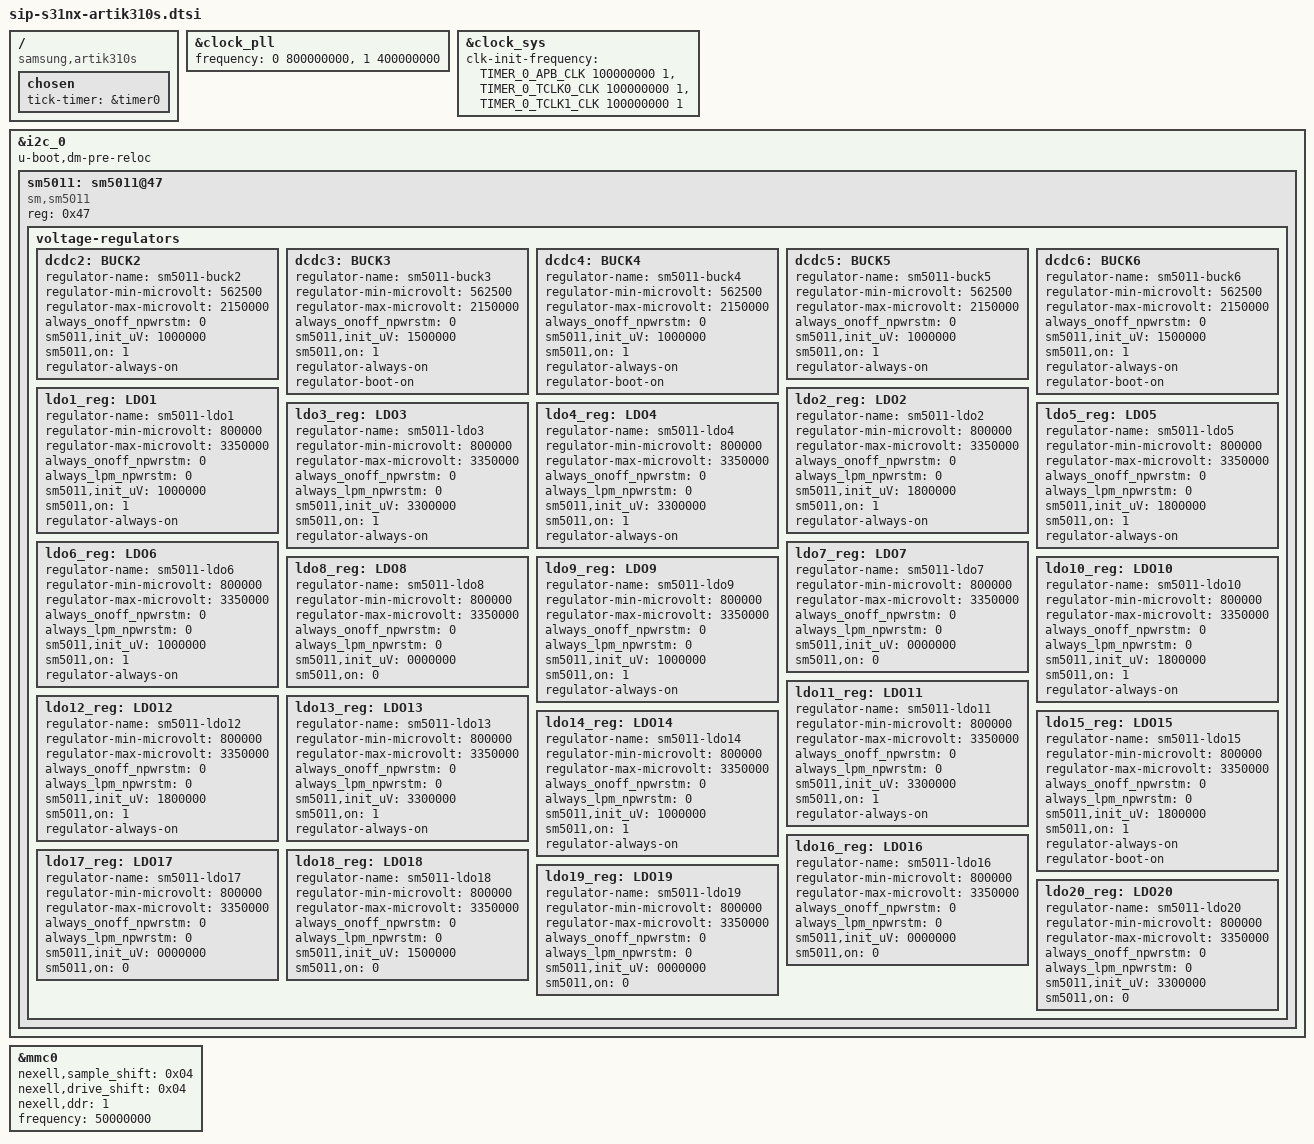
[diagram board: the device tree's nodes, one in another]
/*
 * (C) Copyright 2018 Nexell
 * JungHyun, Kim <jhkim@nexell.co.kr>
 *
 * SPDX-License-Identifier:      GPL-2.0+
 */

#include "sip-s31nx.dtsi"

/ {
	compatible = "samsung,artik310s", "nexell,nxp3220";

	chosen {
		tick-timer = &timer0;
	};
};

&clock_pll {
	frequency = <0 800000000>,
		    <1 400000000>;
};

&clock_sys {
	clk-init-frequency = <TIMER_0_APB_CLK 100000000 1>,
			     <TIMER_0_TCLK0_CLK 100000000 1>,
			     <TIMER_0_TCLK1_CLK 100000000 1>;
};

&i2c_0 {
	status = "okay";
	u-boot,dm-pre-reloc;
	#address-cells = <1>;
	#size-cells = <0>;

	sm5011: sm5011@47 {
		compatible = "sm,sm5011";
		reg = <0x47>;

		voltage-regulators {
			/* BUCK */
			dcdc2: BUCK2 {
				regulator-name = "sm5011-buck2";
				regulator-min-microvolt = <562500>;
				regulator-max-microvolt = <2150000>;
				always_onoff_npwrstm = <0>;
				sm5011,init_uV = <1000000>;
				sm5011,on = <1>;
				regulator-always-on;
			};

			dcdc3: BUCK3 {
				regulator-name = "sm5011-buck3";
				regulator-min-microvolt = <562500>;
				regulator-max-microvolt = <2150000>;
				always_onoff_npwrstm = <0>;
				sm5011,init_uV = <1500000>;
				sm5011,on = <1>;
				regulator-always-on;
				regulator-boot-on;
			};

			dcdc4: BUCK4 {
				regulator-name = "sm5011-buck4";
				regulator-min-microvolt = <562500>;
				regulator-max-microvolt = <2150000>;
				always_onoff_npwrstm = <0>;
				sm5011,init_uV = <1000000>;
				sm5011,on = <1>;
				regulator-always-on;
				regulator-boot-on;
			};

			dcdc5: BUCK5 {
				regulator-name = "sm5011-buck5";
				regulator-min-microvolt = <562500>;
				regulator-max-microvolt = <2150000>;
				always_onoff_npwrstm = <0>;
				sm5011,init_uV = <1000000>;
				sm5011,on = <1>;
				regulator-always-on;
			};

			dcdc6: BUCK6 {
				regulator-name = "sm5011-buck6";
				regulator-min-microvolt = <562500>;
				regulator-max-microvolt = <2150000>;
				always_onoff_npwrstm = <0>;
				sm5011,init_uV = <1500000>;
				sm5011,on = <1>;
				regulator-always-on;
				regulator-boot-on;
			};

			/* LDO */
			ldo1_reg: LDO1 {
				regulator-name = "sm5011-ldo1";
				regulator-min-microvolt = <800000>;
				regulator-max-microvolt = <3350000>;
				always_onoff_npwrstm = <0>;
				always_lpm_npwrstm = <0>;
				sm5011,init_uV = <1000000>;
				sm5011,on = <1>;
				regulator-always-on;
			};

			ldo2_reg: LDO2 {
				regulator-name = "sm5011-ldo2";
				regulator-min-microvolt = <800000>;
				regulator-max-microvolt = <3350000>;
				always_onoff_npwrstm = <0>;
				always_lpm_npwrstm = <0>;
				sm5011,init_uV = <1800000>;
				sm5011,on = <1>;
				regulator-always-on;
			};

			ldo3_reg: LDO3 {
				regulator-name = "sm5011-ldo3";
				regulator-min-microvolt = <800000>;
				regulator-max-microvolt = <3350000>;
				always_onoff_npwrstm = <0>;
				always_lpm_npwrstm = <0>;
				sm5011,init_uV = <3300000>;
				sm5011,on = <1>;
				regulator-always-on;
			};

			ldo4_reg: LDO4 {
				regulator-name = "sm5011-ldo4";
				regulator-min-microvolt = <800000>;
				regulator-max-microvolt = <3350000>;
				always_onoff_npwrstm = <0>;
				always_lpm_npwrstm = <0>;
				sm5011,init_uV = <3300000>;
				sm5011,on = <1>;
				regulator-always-on;
			};

			ldo5_reg: LDO5 {
				regulator-name = "sm5011-ldo5";
				regulator-min-microvolt = <800000>;
				regulator-max-microvolt = <3350000>;
				always_onoff_npwrstm = <0>;
				always_lpm_npwrstm = <0>;
				sm5011,init_uV = <1800000>;
				sm5011,on = <1>;
				regulator-always-on;
			};

			ldo6_reg: LDO6 {
				regulator-name = "sm5011-ldo6";
				regulator-min-microvolt = <800000>;
				regulator-max-microvolt = <3350000>;
				always_onoff_npwrstm = <0>;
				always_lpm_npwrstm = <0>;
				sm5011,init_uV = <1000000>;
				sm5011,on = <1>;
				regulator-always-on;
			};

			ldo7_reg: LDO7 {
				regulator-name = "sm5011-ldo7";
				regulator-min-microvolt = <800000>;
				regulator-max-microvolt = <3350000>;
				always_onoff_npwrstm = <0>;
				always_lpm_npwrstm = <0>;
				sm5011,init_uV = <0000000>;
				sm5011,on = <0>;
			};

			ldo8_reg: LDO8 {
				regulator-name = "sm5011-ldo8";
				regulator-min-microvolt = <800000>;
				regulator-max-microvolt = <3350000>;
				always_onoff_npwrstm = <0>;
				always_lpm_npwrstm = <0>;
				sm5011,init_uV = <0000000>;
				sm5011,on = <0>;
			};

			ldo9_reg: LDO9 {
				regulator-name = "sm5011-ldo9";
				regulator-min-microvolt = <800000>;
				regulator-max-microvolt = <3350000>;
				always_onoff_npwrstm = <0>;
				always_lpm_npwrstm = <0>;
				sm5011,init_uV = <1000000>;
				sm5011,on = <1>;
				regulator-always-on;
			};

			ldo10_reg: LDO10 {
				regulator-name = "sm5011-ldo10";
				regulator-min-microvolt = <800000>;
				regulator-max-microvolt = <3350000>;
				always_onoff_npwrstm = <0>;
				always_lpm_npwrstm = <0>;
				sm5011,init_uV = <1800000>;
				sm5011,on = <1>;
				regulator-always-on;
			};

			ldo11_reg: LDO11 {
				regulator-name = "sm5011-ldo11";
				regulator-min-microvolt = <800000>;
				regulator-max-microvolt = <3350000>;
				always_onoff_npwrstm = <0>;
				always_lpm_npwrstm = <0>;
				sm5011,init_uV = <3300000>;
				sm5011,on = <1>;
				regulator-always-on;
			};

			ldo12_reg: LDO12 {
				regulator-name = "sm5011-ldo12";
				regulator-min-microvolt = <800000>;
				regulator-max-microvolt = <3350000>;
				always_onoff_npwrstm = <0>;
				always_lpm_npwrstm = <0>;
				sm5011,init_uV = <1800000>;
				sm5011,on = <1>;
				regulator-always-on;
			};

			ldo13_reg: LDO13 {
				regulator-name = "sm5011-ldo13";
				regulator-min-microvolt = <800000>;
				regulator-max-microvolt = <3350000>;
				always_onoff_npwrstm = <0>;
				always_lpm_npwrstm = <0>;
				sm5011,init_uV = <3300000>;
				sm5011,on = <1>;
				regulator-always-on;
			};

			ldo14_reg: LDO14 {
				regulator-name = "sm5011-ldo14";
				regulator-min-microvolt = <800000>;
				regulator-max-microvolt = <3350000>;
				always_onoff_npwrstm = <0>;
				always_lpm_npwrstm = <0>;
				sm5011,init_uV = <1000000>;
				sm5011,on = <1>;
				regulator-always-on;
			};

			ldo15_reg: LDO15 {
				regulator-name = "sm5011-ldo15";
				regulator-min-microvolt = <800000>;
				regulator-max-microvolt = <3350000>;
				always_onoff_npwrstm = <0>;
				always_lpm_npwrstm = <0>;
				sm5011,init_uV = <1800000>;
				sm5011,on = <1>;
				regulator-always-on;
				regulator-boot-on;
			};

			ldo16_reg: LDO16 {
				regulator-name = "sm5011-ldo16";
				regulator-min-microvolt = <800000>;
				regulator-max-microvolt = <3350000>;
				always_onoff_npwrstm = <0>;
				always_lpm_npwrstm = <0>;
				sm5011,init_uV = <0000000>;
				sm5011,on = <0>;
			};

			ldo17_reg: LDO17 {
				regulator-name = "sm5011-ldo17";
				regulator-min-microvolt = <800000>;
				regulator-max-microvolt = <3350000>;
				always_onoff_npwrstm = <0>;
				always_lpm_npwrstm = <0>;
				sm5011,init_uV = <0000000>;
				sm5011,on = <0>;
			};

			ldo18_reg: LDO18 {
				regulator-name = "sm5011-ldo18";
				regulator-min-microvolt = <800000>;
				regulator-max-microvolt = <3350000>;
				always_onoff_npwrstm = <0>;
				always_lpm_npwrstm = <0>;
				sm5011,init_uV = <1500000>;
				sm5011,on = <0>;
			};

			ldo19_reg: LDO19 {
				regulator-name = "sm5011-ldo19";
				regulator-min-microvolt = <800000>;
				regulator-max-microvolt = <3350000>;
				always_onoff_npwrstm = <0>;
				always_lpm_npwrstm = <0>;
				sm5011,init_uV = <0000000>;
				sm5011,on = <0>;
			};

			ldo20_reg: LDO20 {
				regulator-name = "sm5011-ldo20";
				regulator-min-microvolt = <800000>;
				regulator-max-microvolt = <3350000>;
				always_onoff_npwrstm = <0>;
				always_lpm_npwrstm = <0>;
				sm5011,init_uV = <3300000>;
				sm5011,on = <0>;
			};
		}; /* voltage-regulators */
	};
};

&mmc0 {
	nexell,sample_shift = <0x04>;
	nexell,drive_shift = <0x04>;
	nexell,ddr = <1>;
	frequency = <50000000>;
	status = "okay";
};
